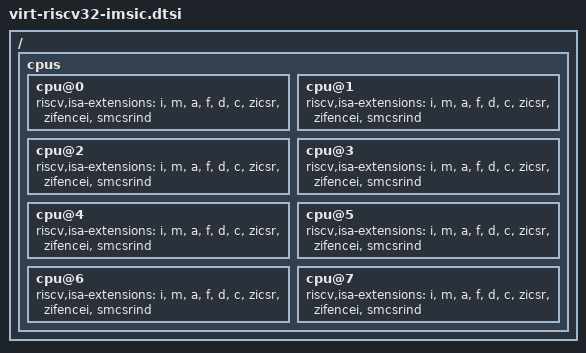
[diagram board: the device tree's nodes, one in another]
/*
 * SPDX-FileCopyrightText: Copyright The Zephyr Project Contributors
 *
 * SPDX-License-Identifier: Apache-2.0
 */

/dts-v1/;

#include <qemu/virt-riscv32.dtsi>

/ {
	cpus {
		cpu@0 {
			riscv,isa-extensions = "i", "m", "a", "f", "d", "c", "zicsr",
					       "zifencei", "smcsrind";
		};

		cpu@1 {
			riscv,isa-extensions = "i", "m", "a", "f", "d", "c", "zicsr",
					       "zifencei", "smcsrind";
		};

		cpu@2 {
			riscv,isa-extensions = "i", "m", "a", "f", "d", "c", "zicsr",
					       "zifencei", "smcsrind";
		};

		cpu@3 {
			riscv,isa-extensions = "i", "m", "a", "f", "d", "c", "zicsr",
					       "zifencei", "smcsrind";
		};

		cpu@4 {
			riscv,isa-extensions = "i", "m", "a", "f", "d", "c", "zicsr",
					       "zifencei", "smcsrind";
		};

		cpu@5 {
			riscv,isa-extensions = "i", "m", "a", "f", "d", "c", "zicsr",
					       "zifencei", "smcsrind";
		};

		cpu@6 {
			riscv,isa-extensions = "i", "m", "a", "f", "d", "c", "zicsr",
					       "zifencei", "smcsrind";
		};

		cpu@7 {
			riscv,isa-extensions = "i", "m", "a", "f", "d", "c", "zicsr",
					       "zifencei", "smcsrind";
		};
	};
};
